# PIC32MX350F128H register map
Vendor: Microchip
Registers are 32-bit, read-write, reset 0x0 unless marked. A register's access mark holds for its fields unless they carry their own. Addresses are absolute, and some are shared; only a register's first bit layout is shown; [hi:lo] are bit positions; {n}, {i} and the like mark numbered series.

## UART1
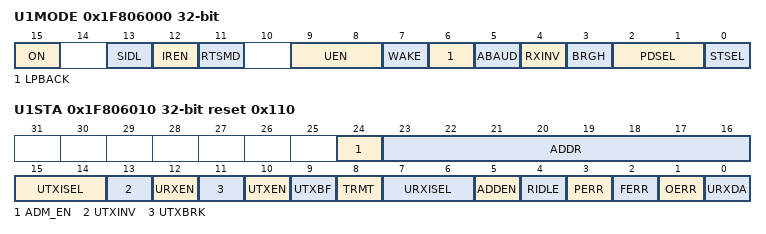
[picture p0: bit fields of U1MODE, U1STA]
0x1F806000 U1MODE
  [15] ON, [13] SIDL, [12] IREN, [11] RTSMD, [9:8] UEN, [7] WAKE, [6] LPBACK, [5] ABAUD, [4] RXINV, [3] BRGH, [2:1] PDSEL, [0] STSEL
0x1F806010 U1STA reset 0x110
  [24] ADM_EN
  [23:16] ADDR
  [15:14] UTXISEL
  [13] UTXINV
  [12] URXEN
  [11] UTXBRK
  [10] UTXEN
  [9] UTXBF ro
  [8] TRMT ro
  [7:6] URXISEL
  [5] ADDEN
  [4] RIDLE ro
  [3] PERR ro
  [2] FERR ro
  [1] OERR — (can only be cleared)
  [0] URXDA ro
0x1F806020 U1TXREG reset not defined — (power-on value -----------------------xxxxxxxxx)
  [8:0] U1TXREG
0x1F806030 U1RXREG ro
  [8:0] U1RXREG
0x1F806040 U1BRG
  [15:0] BRG

## UART2
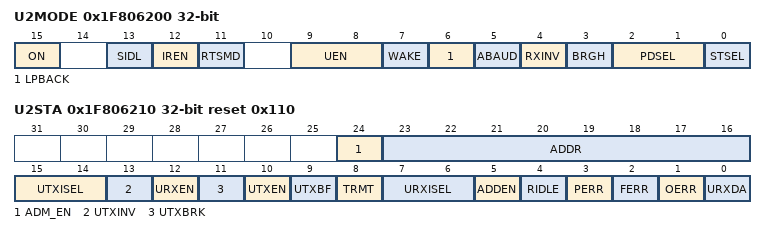
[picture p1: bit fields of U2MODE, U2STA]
0x1F806200 U2MODE
  [15] ON, [13] SIDL, [12] IREN, [11] RTSMD, [9:8] UEN, [7] WAKE, [6] LPBACK, [5] ABAUD, [4] RXINV, [3] BRGH, [2:1] PDSEL, [0] STSEL
0x1F806210 U2STA reset 0x110
  [24] ADM_EN
  [23:16] ADDR
  [15:14] UTXISEL
  [13] UTXINV
  [12] URXEN
  [11] UTXBRK
  [10] UTXEN
  [9] UTXBF ro
  [8] TRMT ro
  [7:6] URXISEL
  [5] ADDEN
  [4] RIDLE ro
  [3] PERR ro
  [2] FERR ro
  [1] OERR — (can only be cleared)
  [0] URXDA ro
0x1F806220 U2TXREG reset not defined — (power-on value -----------------------xxxxxxxxx)
  [8:0] U2TXREG
0x1F806230 U2RXREG ro
  [8:0] U2RXREG
0x1F806240 U2BRG
  [15:0] BRG

## UART3
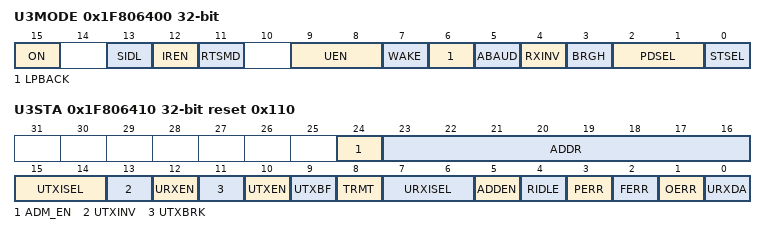
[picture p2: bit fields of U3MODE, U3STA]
0x1F806400 U3MODE
  [15] ON, [13] SIDL, [12] IREN, [11] RTSMD, [9:8] UEN, [7] WAKE, [6] LPBACK, [5] ABAUD, [4] RXINV, [3] BRGH, [2:1] PDSEL, [0] STSEL
0x1F806410 U3STA reset 0x110
  [24] ADM_EN
  [23:16] ADDR
  [15:14] UTXISEL
  [13] UTXINV
  [12] URXEN
  [11] UTXBRK
  [10] UTXEN
  [9] UTXBF ro
  [8] TRMT ro
  [7:6] URXISEL
  [5] ADDEN
  [4] RIDLE ro
  [3] PERR ro
  [2] FERR ro
  [1] OERR — (can only be cleared)
  [0] URXDA ro
0x1F806420 U3TXREG reset not defined — (power-on value -----------------------xxxxxxxxx)
  [8:0] U3TXREG
0x1F806430 U3RXREG ro
  [8:0] U3RXREG
0x1F806440 U3BRG
  [15:0] BRG

## UART4
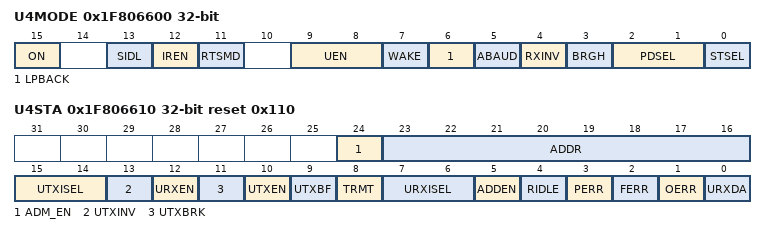
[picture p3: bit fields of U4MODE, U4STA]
0x1F806600 U4MODE
  [15] ON, [13] SIDL, [12] IREN, [11] RTSMD, [9:8] UEN, [7] WAKE, [6] LPBACK, [5] ABAUD, [4] RXINV, [3] BRGH, [2:1] PDSEL, [0] STSEL
0x1F806610 U4STA reset 0x110
  [24] ADM_EN
  [23:16] ADDR
  [15:14] UTXISEL
  [13] UTXINV
  [12] URXEN
  [11] UTXBRK
  [10] UTXEN
  [9] UTXBF ro
  [8] TRMT ro
  [7:6] URXISEL
  [5] ADDEN
  [4] RIDLE ro
  [3] PERR ro
  [2] FERR ro
  [1] OERR — (can only be cleared)
  [0] URXDA ro
0x1F806620 U4TXREG reset not defined — (power-on value -----------------------xxxxxxxxx)
  [8:0] U4TXREG
0x1F806630 U4RXREG ro
  [8:0] U4RXREG
0x1F806640 U4BRG
  [15:0] BRG

## PMP
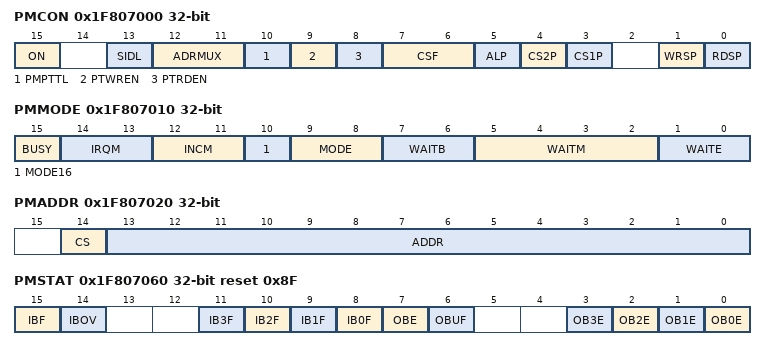
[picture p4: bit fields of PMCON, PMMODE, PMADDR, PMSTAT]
0x1F807000 PMCON
  [15] ON, [13] SIDL, [12:11] ADRMUX, [10] PMPTTL, [9] PTWREN, [8] PTRDEN, [7:6] CSF, [5] ALP, [4] CS2P, [3] CS1P, [1] WRSP, [0] RDSP
0x1F807010 PMMODE
  [15] BUSY ro, [14:13] IRQM, [12:11] INCM, [10] MODE16, [9:8] MODE, [7:6] WAITB, [5:2] WAITM, [1:0] WAITE
0x1F807020 PMADDR
  [14] CS, [13:0] ADDR
0x1F807030 PMDOUT
  [31:0] DATAOUT
0x1F807040 PMDIN
  [31:0] DATAIN
0x1F807050 PMAEN
  [15:0] PTEN
0x1F807060 PMSTAT reset 0x8F
  [15] IBF ro, [14] IBOV, [n+8] IB{n}F ro (n=0..3), [7] OBE ro, [6] OBUF, [n] OB{n}E ro (n=0..3)

## ADC10
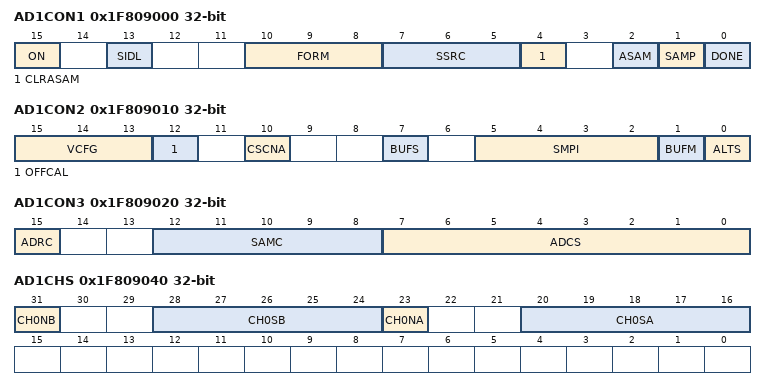
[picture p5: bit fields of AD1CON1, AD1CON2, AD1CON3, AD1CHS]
0x1F809000 AD1CON1
  [15] ON
  [13] SIDL
  [10:8] FORM
  [7:5] SSRC
  [4] CLRASAM
  [2] ASAM
  [1] SAMP
  [0] DONE — (can only be cleared)
0x1F809010 AD1CON2
  [15:13] VCFG, [12] OFFCAL, [10] CSCNA, [7] BUFS ro, [5:2] SMPI, [1] BUFM, [0] ALTS
0x1F809020 AD1CON3
  [15] ADRC, [12:8] SAMC, [7:0] ADCS
0x1F809040 AD1CHS
  [31] CH0NB, [28:24] CH0SB, [23] CH0NA, [20:16] CH0SA
0x1F809050 AD1CSSL
  [30:0] CSSL
{0x1F809070+0x10*i} ADC1BUF{i} ro (i=0..9)
0x1F809110 ADC1BUFA ro
0x1F809120 ADC1BUFB ro
0x1F809130 ADC1BUFC ro
0x1F809140 ADC1BUFD ro
0x1F809150 ADC1BUFE ro
0x1F809160 ADC1BUFF ro

## CVR
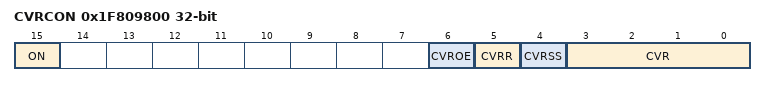
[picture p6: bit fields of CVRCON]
0x1F809800 CVRCON
  [15] ON, [6] CVROE, [5] CVRR, [4] CVRSS, [3:0] CVR

## CMP1
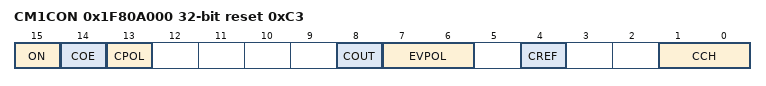
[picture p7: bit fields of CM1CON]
0x1F80A000 CM1CON reset 0xC3
  [15] ON, [14] COE, [13] CPOL, [8] COUT, [7:6] EVPOL, [4] CREF, [1:0] CCH

## CMP2
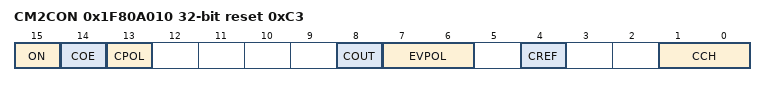
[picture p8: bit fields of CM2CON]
0x1F80A010 CM2CON reset 0xC3
  [15] ON, [14] COE, [13] CPOL, [8] COUT, [7:6] EVPOL, [4] CREF, [1:0] CCH

## cmp_control_pb
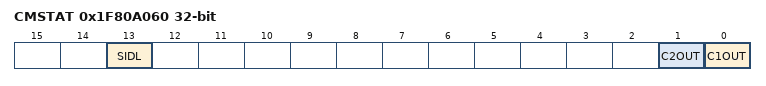
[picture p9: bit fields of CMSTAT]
0x1F80A060 CMSTAT
  [13] SIDL, [1] C2OUT ro, [0] C1OUT ro

## CTMU
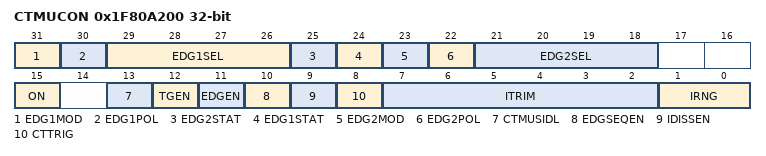
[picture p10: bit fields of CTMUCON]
0x1F80A200 CTMUCON
  [31] EDG1MOD, [30] EDG1POL, [29:26] EDG1SEL, [25] EDG2STAT, [24] EDG1STAT, [23] EDG2MOD, [22] EDG2POL, [21:18] EDG2SEL, [15] ON, [13] CTMUSIDL, [12] TGEN, [11] EDGEN, [10] EDGSEQEN, [9] IDISSEN, [8] CTTRIG, [7:2] ITRIM, [1:0] IRNG

## OSC
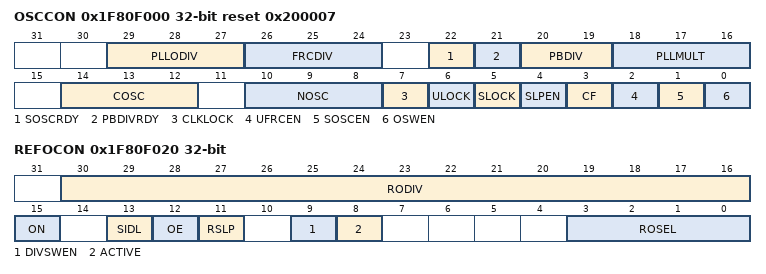
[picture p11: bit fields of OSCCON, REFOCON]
0x1F80F000 OSCCON reset 0x200007
  [29:27] PLLODIV, [26:24] FRCDIV, [22] SOSCRDY, [21] PBDIVRDY, [20:19] PBDIV, [18:16] PLLMULT, [14:12] COSC, [10:8] NOSC, [7] CLKLOCK, [6] ULOCK, [5] SLOCK, [4] SLPEN, [3] CF, [2] UFRCEN, [1] SOSCEN, [0] OSWEN
0x1F80F010 OSCTUN
  [5:0] TUN
0x1F80F020 REFOCON reset not defined — (power-on value -xxxxxxxxxxxxxxxxxxxxxxxx---xxxx)
  [30:16] RODIV, [15] ON, [13] SIDL, [12] OE, [11] RSLP, [9] DIVSWEN, [8] ACTIVE, [3:0] ROSEL
0x1F80F030 REFOTRIM reset not defined — (power-on value xxxxxxxxx-----------------------)
  [31:23] ROTRIM

## CFG
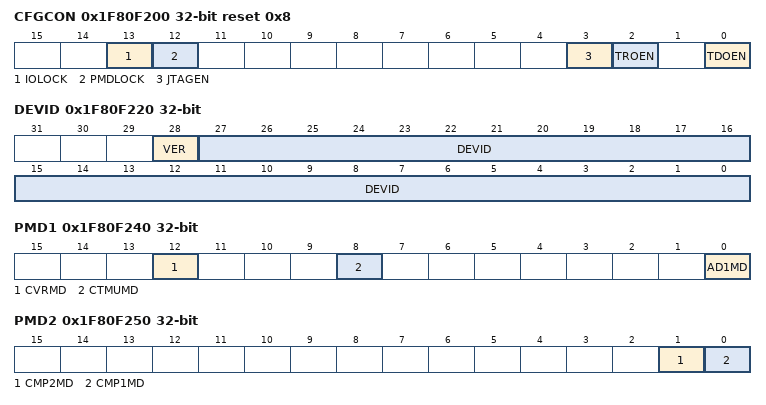
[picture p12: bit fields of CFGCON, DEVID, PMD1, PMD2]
0x1F80F200 CFGCON reset 0x8
  [13] IOLOCK, [12] PMDLOCK, [3] JTAGEN, [2] TROEN, [0] TDOEN
0x1F80F220 DEVID ro reset not defined — (power-on value xxxxxxxxxxxxxxxxxxxxxxxxxxxxxxxx)
  [28] VER, [27:0] DEVID
0x1F80F230 SYSKEY ro reset not defined — (power-on value xxxxxxxxxxxxxxxxxxxxxxxxxxxxxxxx)
0x1F80F240 PMD1
  [12] CVRMD, [8] CTMUMD, [0] AD1MD
0x1F80F250 PMD2
  [1] CMP2MD, [0] CMP1MD
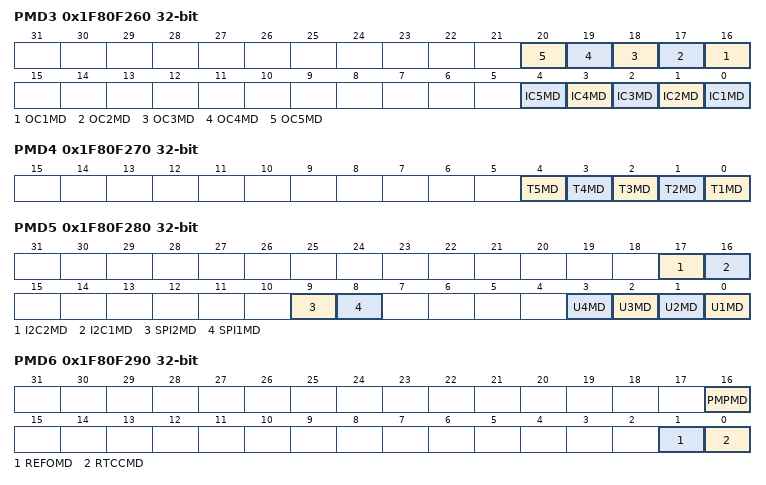
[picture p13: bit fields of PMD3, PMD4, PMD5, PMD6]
0x1F80F260 PMD3
  [n+15] OC{n}MD (n=1..5), [n-1] IC{n}MD (n=1..5)
0x1F80F270 PMD4
  [n-1] T{n}MD (n=1..5)
0x1F80F280 PMD5 reset not defined — (power-on value --------------00------00----xx00)
  [17] I2C2MD, [16] I2C1MD, [9] SPI2MD, [8] SPI1MD, [n-1] U{n}MD (n=1..4)
0x1F80F290 PMD6
  [16] PMPMD, [1] REFOMD, [0] RTCCMD

## NVM
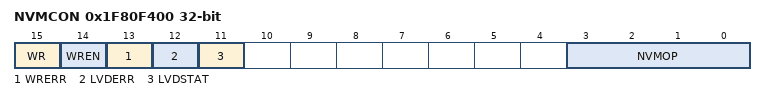
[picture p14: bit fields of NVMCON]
0x1F80F400 NVMCON
  [15] WR, [14] WREN, [13] WRERR, [12] LVDERR, [11] LVDSTAT, [3:0] NVMOP
0x1F80F410 NVMKEY wo
0x1F80F420 NVMADDR
0x1F80F430 NVMDATA
0x1F80F440 NVMSRCADDR

## RCON
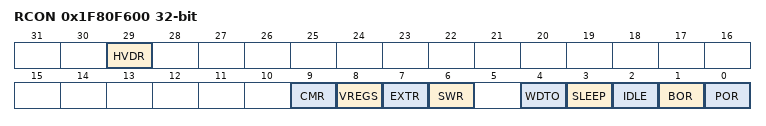
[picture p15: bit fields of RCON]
0x1F80F600 RCON reset not defined — (power-on value --x-------------------0000-00011)
  [29] HVDR, [9] CMR, [8] VREGS, [7] EXTR, [6] SWR, [4] WDTO, [3] SLEEP, [2] IDLE, [1] BOR, [0] POR
0x1F80F610 RSWRST
  [0] SWRST

## RPINRx
{0x1F80FA00+4i} INT{i}R (i=1..4)
  [3:0] INT{i}R
{0x1F80FA10+4i} T{i}CKR (i=2..5)
  [3:0] T{i}CKR
{0x1F80FA24+4i} IC{i}R (i=1..5)
  [3:0] IC{i}R
0x1F80FA48 OCFAR
  [3:0] OCFAR
{0x1F80FA48+8i} U{i}RXR (i=1..5)
  [3:0] U{i}RXR
{0x1F80FA4C+8i} U{i}CTSR (i=1..5)
  [3:0] U{i}CTSR
0x1F80FA84 SDI1R
  [3:0] SDI1R
0x1F80FA88 SS1R
  [3:0] SS1R
0x1F80FA90 SDI2R
  [3:0] SDI2R
0x1F80FA94 SS2R
  [3:0] SS2R
0x1F80FAD0 REFCLKIR
  [3:0] REFCLKIR

## RPORx
{0x1F80FB40+4i} RPB{i}R (i=0..3)
  [3:0] RPB{i}R
{0x1F80FB40+4i} RPB{i}R (i=5..10)
  [3:0] RPB{i}R
0x1F80FB78 RPB14R
  [3:0] RPB14R
0x1F80FB7C RPB15R
  [3:0] RPB15R
0x1F80FBB4 RPC13R
  [3:0] RPC13R
0x1F80FBB8 RPC14R
  [3:0] RPC14R
{0x1F80FBC0+4i} RPD{i}R (i=0..5)
  [3:0] RPD{i}R
{0x1F80FBC0+4i} RPD{i}R (i=8..11)
  [3:0] RPD{i}R
0x1F80FC0C RPE3R
  [3:0] RPE3R
0x1F80FC14 RPE5R
  [3:0] RPE5R
{0x1F80FC40+4i} RPF{i}R (i=0..6)
  [3:0] RPF{i}R
{0x1F80FC80+4i} RPG{i}R (i=6..9)
  [3:0] RPG{i}R
